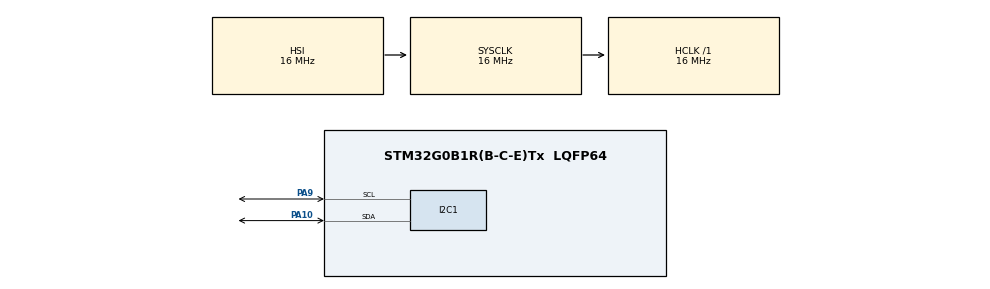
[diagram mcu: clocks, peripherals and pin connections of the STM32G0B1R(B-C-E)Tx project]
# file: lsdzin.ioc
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Mcu.Family=STM32G0
Mcu.Name=STM32G0B1R(B-C-E)Tx
Mcu.Package=LQFP64
PA10.Mode=I2C
PA10.Signal=I2C1_SDA
PA13.Mode=Serial_Wire
PA13.Signal=SYS_SWDIO
PA14-BOOT0.Mode=Serial_Wire
PA14-BOOT0.Signal=SYS_SWCLK
PA9.Mode=I2C
PA9.Signal=I2C1_SCL
PC14-OSC32_IN\ (PC14).Mode=LSE-External-Oscillator
PC14-OSC32_IN\ (PC14).Signal=RCC_OSC32_IN
PC15-OSC32_OUT\ (PC15).Mode=LSE-External-Oscillator
PC15-OSC32_OUT\ (PC15).Signal=RCC_OSC32_OUT
PF0-OSC_IN\ (PF0).Mode=HSE-External-Oscillator
PF0-OSC_IN\ (PF0).Signal=RCC_OSC_IN
PF1-OSC_OUT\ (PF1).Mode=HSE-External-Oscillator
PF1-OSC_OUT\ (PF1).Signal=RCC_OSC_OUT
ProjectManager.HeapSize=0x200
ProjectManager.StackSize=0x400
ProjectManager.TargetToolchain=STM32CubeIDE
RCC.AHBFreq_Value=16000000
RCC.CortexFreq_Value=16000000
RCC.EXTERNAL_CLOCK_VALUE=48000
RCC.HCLKFreq_Value=16000000
RCC.HSE_VALUE=8000000
RCC.HSI48_VALUE=48000000
RCC.HSI_VALUE=16000000
RCC.SYSCLKFreq_VALUE=16000000
RCC.USBFreq_Value=48000000
RCC.VCOOutputFreq_Value=128000000
VP_SYS_VS_DBSignals.Mode=DisableDeadBatterySignals
board=custom

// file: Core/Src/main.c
/* USER CODE BEGIN Header */
/**
  ******************************************************************************
  * @file           : main.c
  * @brief          : Main program body
  ******************************************************************************
  * @attention
  *
  * Copyright (c) 2022 STMicroelectronics.
  * All rights reserved.
  *
  * This software is licensed under terms that can be found in the LICENSE file
  * in the root directory of this software component.
  * If no LICENSE file comes with this software, it is provided AS-IS.
  *
  ******************************************************************************
  */
/* USER CODE END Header */
#include "main.h"

/* USER CODE BEGIN Includes */
#include "liquidcrystal_i2c.h"

/* USER CODE END Includes */

I2C_HandleTypeDef hi2c1;

void SystemClock_Config(void);
static void MX_GPIO_Init(void);
static void MX_I2C1_Init(void);

/* USER CODE BEGIN 0 */
uint16_t x;
uint8_t special1[8] = {
        0b00000,
        0b11001,
        0b11011,
        0b00110,
        0b01100,
        0b11011,
        0b10011,
        0b00000
};

/* USER CODE END 0 */

int main(void)
{

  /* MCU Configuration--------------------------------------------------------*/

  /* Reset of all peripherals, Initializes the Flash interface and the Systick. */
  HAL_Init();

  /* Configure the system clock */
  SystemClock_Config();

  /* Initialize all configured peripherals */
  MX_GPIO_Init();
  MX_I2C1_Init();
  /* USER CODE BEGIN 2 */

  HD44780_Init(2);

  HD44780_CreateSpecialChar(0, special1);

    HD44780_Clear();
    HD44780_SetCursor(0,0);
    HD44780_PrintStr("teSte");
    HD44780_SetCursor(9,1);
    HD44780_PrintStr("TEsTe");
    HAL_Delay(2000);

    HD44780_Clear();
    HD44780_SetCursor(0,0);
    HD44780_PrintStr("bao fi");
    HAL_Delay(2000);
    HD44780_NoBacklight();
    HAL_Delay(2000);
    HD44780_Backlight();

    HAL_Delay(2000);
    HD44780_Cursor();
    HAL_Delay(2000);
    HD44780_Blink();
    HAL_Delay(5000);
    HD44780_NoBlink();
    HAL_Delay(2000);
    HD44780_NoCursor();
    HAL_Delay(2000);

    HD44780_NoDisplay();
    HAL_Delay(2000);
    HD44780_Display();

    HD44780_Clear();
    HD44780_SetCursor(0,0);
    HD44780_PrintStr("Opa eae vei blz?:-)");

    for(int x=0; x<40; x=x+1)
    {
      HD44780_ScrollDisplayLeft();  //HD44780_ScrollDisplayRight();
      HAL_Delay(500);
    }

    char snum[5];
    for ( int x = 1; x <= 200 ; x++ )

    {
      itoa(x, snum, 10);
      HD44780_Clear();
      HD44780_SetCursor(0,0);
      HD44780_PrintStr(snum);
      HAL_Delay (500);
    }
  /* USER CODE END 2 */

  /* Infinite loop */
  while (1)
  {

  }
}

void SystemClock_Config(void)
{
  RCC_OscInitTypeDef RCC_OscInitStruct = {0};
  RCC_ClkInitTypeDef RCC_ClkInitStruct = {0};

  /** Configure the main internal regulator output voltage
  */
  HAL_PWREx_ControlVoltageScaling(PWR_REGULATOR_VOLTAGE_SCALE1);
  /** Initializes the RCC Oscillators according to the specified parameters
  * in the RCC_OscInitTypeDef structure.
  */
  RCC_OscInitStruct.OscillatorType = RCC_OSCILLATORTYPE_HSI;
  RCC_OscInitStruct.HSIState = RCC_HSI_ON;
  RCC_OscInitStruct.HSIDiv = RCC_HSI_DIV1;
  RCC_OscInitStruct.HSICalibrationValue = RCC_HSICALIBRATION_DEFAULT;
  RCC_OscInitStruct.PLL.PLLState = RCC_PLL_NONE;
  if (HAL_RCC_OscConfig(&RCC_OscInitStruct) != HAL_OK)
  {
    Error_Handler();
  }
  /** Initializes the CPU, AHB and APB buses clocks
  */
  RCC_ClkInitStruct.ClockType = RCC_CLOCKTYPE_HCLK|RCC_CLOCKTYPE_SYSCLK
                              |RCC_CLOCKTYPE_PCLK1;
  RCC_ClkInitStruct.SYSCLKSource = RCC_SYSCLKSOURCE_HSI;
  RCC_ClkInitStruct.AHBCLKDivider = RCC_SYSCLK_DIV1;
  RCC_ClkInitStruct.APB1CLKDivider = RCC_HCLK_DIV1;

  if (HAL_RCC_ClockConfig(&RCC_ClkInitStruct, FLASH_LATENCY_0) != HAL_OK)
  {
    Error_Handler();
  }
}

static void MX_I2C1_Init(void)
{

  hi2c1.Instance = I2C1;
  hi2c1.Init.Timing = 0x00303D5B;
  hi2c1.Init.OwnAddress1 = 0;
  hi2c1.Init.AddressingMode = I2C_ADDRESSINGMODE_7BIT;
  hi2c1.Init.DualAddressMode = I2C_DUALADDRESS_DISABLE;
  hi2c1.Init.OwnAddress2 = 0;
  hi2c1.Init.OwnAddress2Masks = I2C_OA2_NOMASK;
  hi2c1.Init.GeneralCallMode = I2C_GENERALCALL_DISABLE;
  hi2c1.Init.NoStretchMode = I2C_NOSTRETCH_DISABLE;
  if (HAL_I2C_Init(&hi2c1) != HAL_OK)
  {
    Error_Handler();
  }
  /** Configure Analogue filter
  */
  if (HAL_I2CEx_ConfigAnalogFilter(&hi2c1, I2C_ANALOGFILTER_ENABLE) != HAL_OK)
  {
    Error_Handler();
  }
  /** Configure Digital filter
  */
  if (HAL_I2CEx_ConfigDigitalFilter(&hi2c1, 0) != HAL_OK)
  {
    Error_Handler();
  }

}

static void MX_GPIO_Init(void)
{

  /* GPIO Ports Clock Enable */
  __HAL_RCC_GPIOC_CLK_ENABLE();
  __HAL_RCC_GPIOF_CLK_ENABLE();
  __HAL_RCC_GPIOA_CLK_ENABLE();

}

void Error_Handler(void)
{
  __disable_irq();
  while (1)
  {
  }
}
